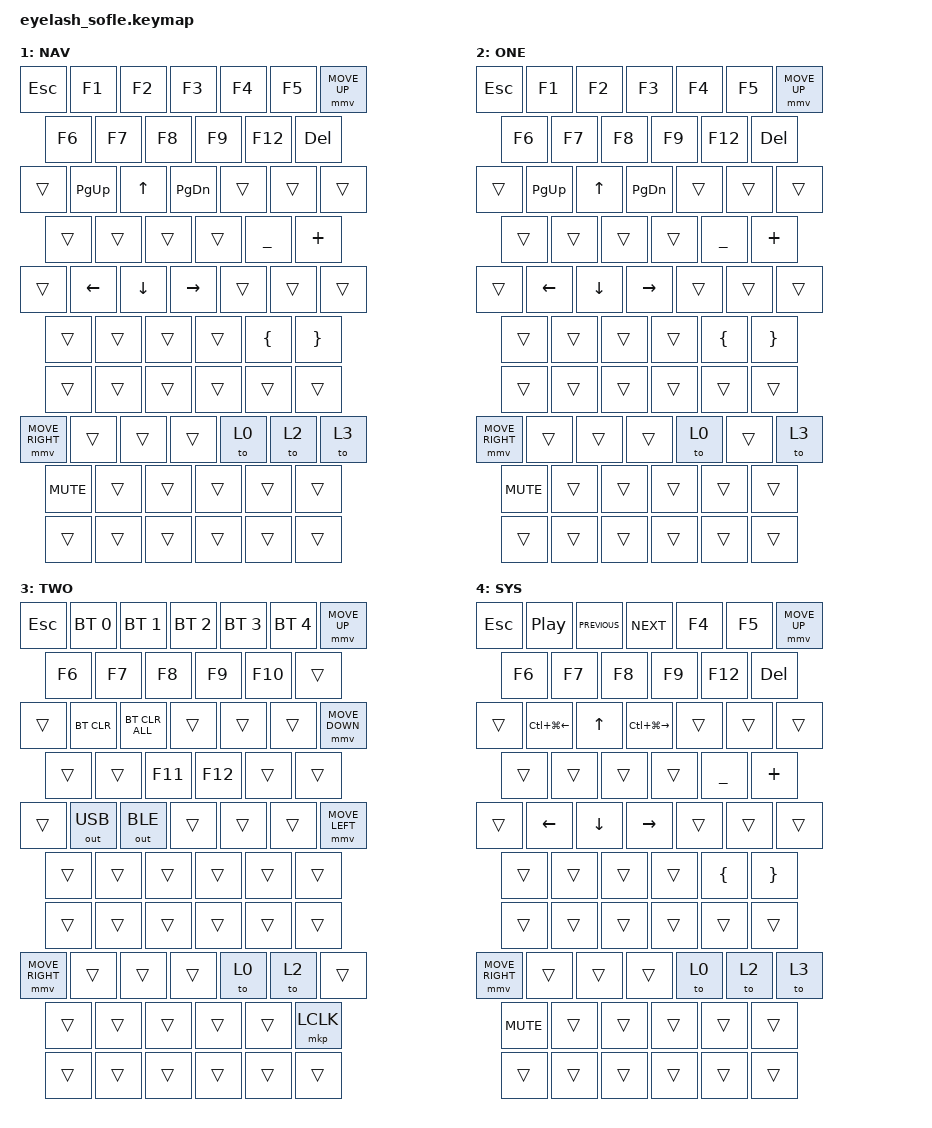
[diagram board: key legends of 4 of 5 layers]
#define ZMK_POINTING_DEFAULT_MOVE_VAL 1200  // 600
#define ZMK_POINTING_DEFAULT_SCRL_VAL 25    // 10

#include <input/processors.dtsi>
#include <zephyr/dt-bindings/input/input-event-codes.h>
#include <behaviors.dtsi>
#include <dt-bindings/zmk/bt.h>
#include <dt-bindings/zmk/ext_power.h>
#include <dt-bindings/zmk/keys.h>
#include <dt-bindings/zmk/pointing.h>
#include <dt-bindings/zmk/outputs.h>

//  SOFLE "3C" AliExpress - Nice!View Edition
//
//	┌────┬────┬────┬────┬────┬────┐               ┌────┬────┬────┬────┬────┬────┐
//	│  0 │  1 │  2 │  3 │  4 │  5 │               │  7 │  8 │  9 │ 10 │ 11 │ 12 │
//	├────┼────┼────┼────┼────┼────┤               ├────┼────┼────┼────┼────┼────┤
//	│ 13 │ 14 │ 15 │ 16 │ 17 │ 18 │               │ 20 │ 21 │ 22 │ 23 │ 24 │ 25 │
//	├────┼────┼────┼────┼────┼────┤               ├────┼────┼────┼────┼────┼────┤
//	│ 26 │ 27 │ 28 │ 29 │ 30 │ 31 │               │ 33 │ 34 │ 35 │ 36 │ 37 │ 38 │
//	├────┼────┼────┼────┼────┼────┤               ├────┼────┼────┼────┼────┼────┤
//	│ 39 │ 40 │ 41 │ 42 │ 43 │ 44 │               │ 46 │ 47 │ 48 │ 49 │ 50 │ 51 │
//	└────┴────┼────┼────┼────┼────┼────┐     ┌────┼────┼────┼────┼────┼────┴────┘
//			      │ 53 │ 54 │ 55 │ 56 │ 57 │     │ 59 │ 60 │ 61 │ 62 │ 63 │
//			      └────┴────┴────┴────┴────┘     └────┴────┴────┴────┴────┘
//
//						           ROTARY ENC                5-WAY HAT
//						           ┌─────────────┐     ┌─────────────┐
//						           │      52     │     │      6      │
//						           │ X  ← ● →  Y │     │      ↑ 58   │
//						           └─────────────┘     │ 32 ← ● → 45 │
//											                     │      ↓      │
//							            			           │     19      │
//              									           └─────────────┘

/ {
    macros {
        hyper_m: hyper_m {
            label = "HYPER";
            compatible = "zmk,behavior-macro";
            #binding-cells = <0>;
            bindings = <&kp RSHFT &kp RALT &kp RCTRL &kp RGUI>; // Press all the modifiers
            // Use LEFT modifiers if preferred: <&kp LSHFT &kp LALT &kp LCTRL &kp LGUI>;
        };
    };
};

/ {
  combos {
    compatible = "zmk,combos";
    combo_capslock {
      timeout-ms = <30>;
      key-positions = <39 51>; // LSHIFT + RSHIFT
      bindings = <&kp CAPS>;
    };

    combo_ctrl_a {
      timeout-ms = <30>;
      key-positions = <41 42>; // Z + X
      bindings = <&kp LC(A)>;
      layers = <0>;
    };

    combo_ctrl_c {
      timeout-ms = <30>;
      key-positions = <42 43>; // X + C
      bindings = <&kp LC(C)>;
      layers = <0>;
    };

    combo_ctrl_v {
      timeout-ms = <30>;
      key-positions = <43 44>; // C + V
      bindings = <&kp LC(V)>;
      layers = <0>;
    };
  };
};

/ {
  scroll_encoder: scroll_encoder {
    compatible = "zmk,behavior-sensor-rotate";
    #sensor-binding-cells = <0>;
    bindings = <&msc SCRL_DOWN>, <&msc SCRL_UP>;
    tap-ms = <100>;
  };
};

&mmv_input_listener {
  input-processors = <&zip_xy_scaler 2 1>;
};

&msc_input_listener {
  input-processors = <&zip_scroll_scaler 2 1>;
};

&msc {
  acceleration-exponent = <1>;
  time-to-max-speed-ms = <100>;
  delay-ms = <0>;
};

&mmv {
  time-to-max-speed-ms = <500>;
  acceleration-exponent = <1>;
  trigger-period-ms = <16>;
};

/ {
  keymap {
    compatible = "zmk,keymap";

layer_ZERO {
  bindings = <
    // ROW 1
    //  0           1           2           3           4             5           6 (HAT UP)
        &kp GRAVE   &kp N1      &kp N2      &kp N3      &kp N4        &kp N5      &kp UP_ARROW
    //  7           8           9           10          11            12
        &kp N6      &kp N7      &kp N8      &kp N9      &kp N0        &kp BACKSPACE

    // ROW 2
    //  13          14          15          16          17            18          19 (HAT DOWN)
        &kp TAB     &kp Q       &kp W       &kp E       &kp R         &kp T       &kp DOWN_ARROW
    //  20          21          22          23          24            25
        &kp Y       &kp U       &kp I       &kp O       &kp P         &kp BSLH

    // ROW 3
    //  26          27          28          29          30            31          32 (HAT LEFT)
        &kp LALT    &kp A       &kp S       &kp D       &kp F         &kp G       &kp LEFT_ARROW
    //  33          34          35          36          37            38
        &kp H       &kp J       &kp K       &kp L       &kp SEMI      &kp APOS

    // ROW 4
    //  39          40          41          42          43            44          45 (HAT RIGHT)
        &kp LSHFT   &kp Z       &kp X       &kp C       &kp V         &kp B       &kp RIGHT_ARROW
    //  46          47          48          49          50            51
        &kp N       &kp M       &kp COMMA   &kp DOT     &kp FSLH      &kp CAPS

    // ROW 5
    //  53          54          55          56          57            58
        &kp LGUI    &kp LCTRL   &mo 4       &kp SPACE   &kp ESC       &kp A
    //  59          60          61          62          63
        &hyper_m    &kp ENTER   &mo 1       &kp LGUI    &kp A

  >;

  sensor-bindings = <&inc_dec_kp C_VOLUME_UP C_VOLUME_DOWN>;
  display-name = "BASE";
};


    layer_ONE {
      bindings = <
        &kp ESC &kp F1 &kp F2 &kp F3 &kp F4 &kp F5 &mmv MOVE_UP
        &kp F6 &kp F7 &kp F8 &kp F9 &kp F12 &kp DEL

        &trans &kp PG_UP &kp UP &kp PG_DN &trans &trans &trans
        &trans &trans &trans &trans &kp UNDER &kp PLUS

        &trans &kp LEFT &kp DOWN &kp RIGHT &trans &trans &trans
        &trans &trans &trans &trans &kp LBRC &kp RBRC

        &trans &trans &trans &trans &trans &trans
        &mmv MOVE_RIGHT &trans &trans &trans &to 0 &to 2 &to 3

        &kp C_MUTE &trans &trans &trans &trans &trans
        &trans &trans &trans &trans &trans &trans
      >;
      sensor-bindings = <&scroll_encoder>;
      display-name = "NAV";
    };

    layer_TWO {
      bindings = <
        &kp ESC &kp F1 &kp F2 &kp F3 &kp F4 &kp F5 &mmv MOVE_UP
        &kp F6 &kp F7 &kp F8 &kp F9 &kp F12 &kp DEL

        &trans &kp PG_UP &kp UP &kp PG_DN &trans &trans &trans
        &trans &trans &trans &trans &kp UNDER &kp PLUS

        &trans &kp LEFT &kp DOWN &kp RIGHT &trans &trans &trans
        &trans &trans &trans &trans &kp LBRC &kp RBRC

        &trans &trans &trans &trans &trans &trans
        &mmv MOVE_RIGHT &trans &trans &trans &to 0 &trans &to 3

        &kp C_MUTE &trans &trans &trans &trans &trans
        &trans &trans &trans &trans &trans &trans
      >;
      sensor-bindings = <&scroll_encoder>;
      display-name = "ONE";
    };

    layer_THREE {
      bindings = <
        &kp ESC &bt BT_SEL 0 &bt BT_SEL 1 &bt BT_SEL 2 &bt BT_SEL 3 &bt BT_SEL 4 &mmv MOVE_UP
        &kp F6 &kp F7 &kp F8 &kp F9 &kp F10 &trans

        &trans &bt BT_CLR &bt BT_CLR_ALL &trans &trans &trans &mmv MOVE_DOWN
        &trans &trans &kp F11 &kp F12 &trans &trans

        &trans &out OUT_USB &out OUT_BLE &trans &trans &trans &mmv MOVE_LEFT
        &trans &trans &trans &trans &trans &trans

        &trans &trans &trans &trans &trans &trans &mmv MOVE_RIGHT
        &trans &trans &trans &to 0 &to 2 &trans

        &trans &trans &trans &trans &trans &mkp LCLK
        &trans &trans &trans &trans &trans &trans
      >;
      sensor-bindings = <&scroll_encoder>;
      display-name = "TWO";
    };

    layer_FOUR {
      bindings = <
        &kp ESC &kp C_PLAY_PAUSE &kp C_PREVIOUS &kp C_NEXT &kp F4 &kp F5 &mmv MOVE_UP
        &kp F6 &kp F7 &kp F8 &kp F9 &kp F12 &kp DEL

        &trans &kp LC(LG(LEFT_ARROW)) &kp UP &kp LC(LG(RIGHT_ARROW)) &trans &trans &trans
        &trans &trans &trans &trans &kp UNDER &kp PLUS

        &trans &kp LEFT &kp DOWN &kp RIGHT &trans &trans &trans
        &trans &trans &trans &trans &kp LBRC &kp RBRC

        &trans &trans &trans &trans &trans &trans
        &mmv MOVE_RIGHT &trans &trans &trans &to 0 &to 2 &to 3

        &kp C_MUTE &trans &trans &trans &trans &trans
        &trans &trans &trans &trans &trans &trans
      >;
      sensor-bindings = <&scroll_encoder>;
      display-name = "SYS";
    };
  };
};

